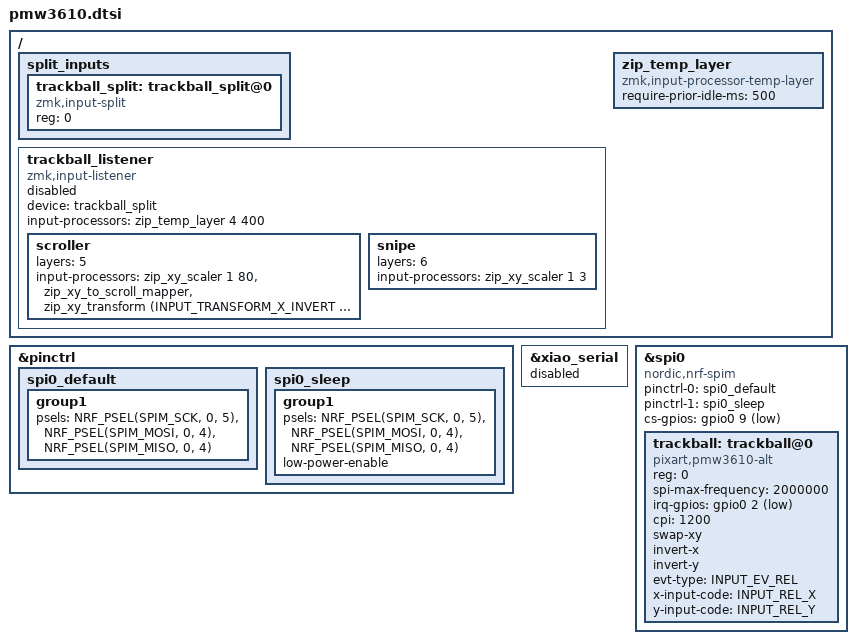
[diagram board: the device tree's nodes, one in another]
#include <input/processors.dtsi>
#include <dt-bindings/zmk/input_transform.h>
#define INPUT_EV_KEY 0x01               /**< Key event */
#define INPUT_EV_REL 0x02               /**< Relative coordinate event */
#define INPUT_EV_ABS 0x03               /**< Absolute coordinate event */
#define INPUT_EV_MSC 0x04               /**< Miscellaneous event */
#define INPUT_EV_VENDOR_START 0xf0      /**< Vendor specific event start */
#define INPUT_EV_VENDOR_STOP 0xff       /**< Vendor specific event stop */

#define INPUT_REL_X 0x00                /**< Relative X coordinate */
#define INPUT_REL_Y 0x01                /**< Relative Y coordinate */
#define INPUT_REL_WHEEL 0x08            /**< Relative wheel coordinate */
#define INPUT_REL_HWHEEL 0x06          /**< Relative horizontal wheel coordinate */
#define INPUT_REL_MISC 0x09             /**< Relative misc coordinate */

&pinctrl {
	spi0_default: spi0_default {
		group1 {
			psels = <NRF_PSEL(SPIM_SCK, 0, 5)>,
				<NRF_PSEL(SPIM_MOSI, 0, 4)>,
				<NRF_PSEL(SPIM_MISO, 0, 4)>;
		};
	};

	spi0_sleep: spi0_sleep {
		group1 {
			psels = <NRF_PSEL(SPIM_SCK, 0, 5)>,
				<NRF_PSEL(SPIM_MOSI, 0, 4)>,
				<NRF_PSEL(SPIM_MISO, 0, 4)>;
			low-power-enable;
		};
	};
};

&xiao_serial { status = "disabled"; };

&spi0 {
  status = "okay";
  compatible = "nordic,nrf-spim";
  pinctrl-0 = <&spi0_default>;
  pinctrl-1 = <&spi0_sleep>;
  pinctrl-names = "default", "sleep";
  cs-gpios = <&gpio0 9 GPIO_ACTIVE_LOW>;
  
  trackball: trackball@0 {
    status = "okay";
    compatible = "pixart,pmw3610-alt";
    reg = <0>;
    spi-max-frequency = <2000000>;
    irq-gpios = <&gpio0 2 (GPIO_ACTIVE_LOW | GPIO_PULL_UP)>;
    cpi = <1200>;
    swap-xy;
    invert-x;
    invert-y;
    evt-type = <INPUT_EV_REL>;
    x-input-code = <INPUT_REL_X>;
    y-input-code = <INPUT_REL_Y>;
	};
};

/ {
    split_inputs {
        #address-cells = <1>;
        #size-cells = <0>;

        trackball_split: trackball_split@0 {
            compatible = "zmk,input-split";
            reg = <0>;
        };
    };

    trackball_listener: trackball_listener{
        compatible = "zmk,input-listener";
        status = "disabled";
        device = <&trackball_split>;
        input-processors = <&zip_temp_layer 4 400>;
        scroller {
            layers = <5>;
            input-processors = <&zip_xy_scaler 1 80>, <&zip_xy_to_scroll_mapper>, <&zip_xy_transform (INPUT_TRANSFORM_X_INVERT | INPUT_TRANSFORM_Y_INVERT)>;
        };

        snipe {
            layers = <6>;
            input-processors = <&zip_xy_scaler 1 3>;
        };
    };

    /omit-if-no-ref/ zip_temp_layer: zip_temp_layer {
      compatible = "zmk,input-processor-temp-layer";
      #input-processor-cells = <2>;
      require-prior-idle-ms = <500>;
    };
};
